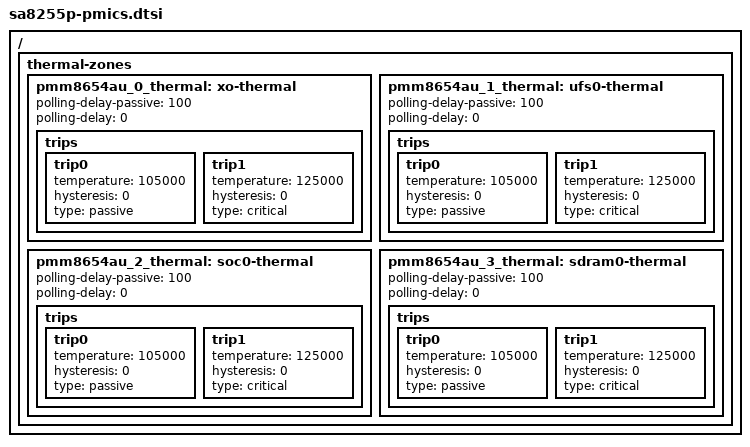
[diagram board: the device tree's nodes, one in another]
// SPDX-License-Identifier: BSD-3-Clause
/*
 * Copyright (c) 2024-2025, Qualcomm Innovation Center, Inc. All rights reserved.
 */

/ {
	thermal-zones {
		pmm8654au_0_thermal: xo-thermal {
			polling-delay-passive = <100>;
			polling-delay = <0>;

			trips {
				trip0 {
					temperature = <105000>;
					hysteresis = <0>;
					type = "passive";
				};

				trip1 {
					temperature = <125000>;
					hysteresis = <0>;
					type = "critical";
				};
			};
		};

		pmm8654au_1_thermal: ufs0-thermal {
			polling-delay-passive = <100>;
			polling-delay = <0>;

			trips {
				trip0 {
					temperature = <105000>;
					hysteresis = <0>;
					type = "passive";
				};

				trip1 {
					temperature = <125000>;
					hysteresis = <0>;
					type = "critical";
				};
			};
		};

		pmm8654au_2_thermal: soc0-thermal {
			polling-delay-passive = <100>;
			polling-delay = <0>;

			trips {
				trip0 {
					temperature = <105000>;
					hysteresis = <0>;
					type = "passive";
				};

				trip1 {
					temperature = <125000>;
					hysteresis = <0>;
					type = "critical";
				};
			};
		};

		pmm8654au_3_thermal: sdram0-thermal {
			polling-delay-passive = <100>;
			polling-delay = <0>;

			trips {
				trip0 {
					temperature = <105000>;
					hysteresis = <0>;
					type = "passive";
				};

				trip1 {
					temperature = <125000>;
					hysteresis = <0>;
					type = "critical";
				};
			};
		};
	};
};
